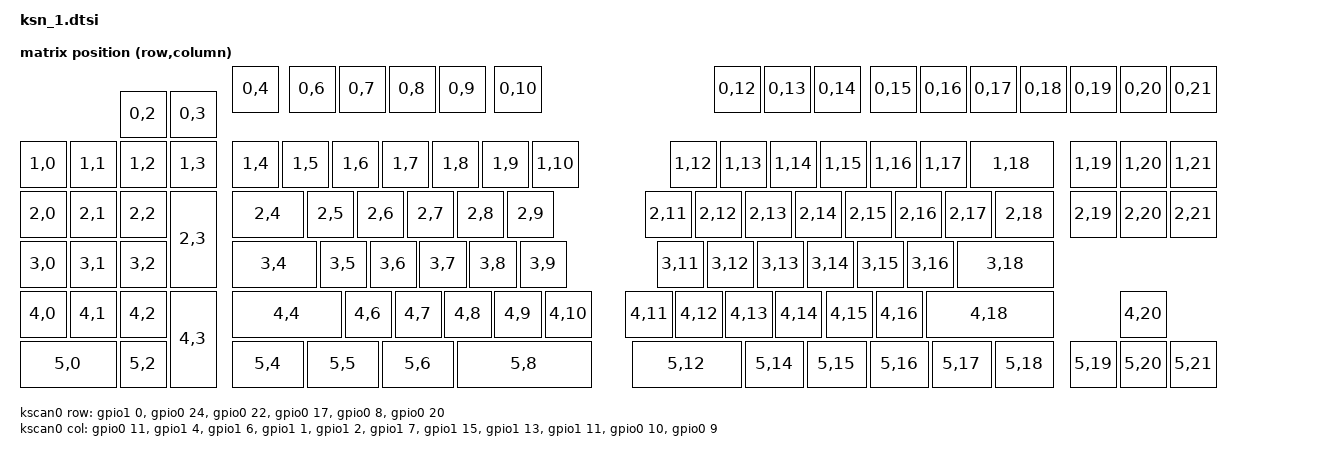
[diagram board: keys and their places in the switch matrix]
#include <dt-bindings/zmk/matrix_transform.h>
#include <physical_layouts.dtsi>

/ {
    chosen {
        zmk,kscan            = &kscan0;
        /* ZMK Studio용: matrix_transform 대신 physical layout을 chosen으로 지정 */
        zmk,physical-layout  = &default_layout;
        zmk,backlight        = &backlight;   /* 추가 */
        /* zmk,battery 는 nice!nano v2 보드 기본값(zmk,battery-nrf-vddh, 내장 VDDH 센싱)을
           그대로 사용. 예전 외부 분배저항(R-1/R-2) 기반 커스텀 vbatt 노드는 부정확한
           수치(528mV/0% 같은)를 냈기 때문에 제거함. */
    };

    default_transform: matrix_transform {
        compatible = "zmk,matrix-transform";
        columns = <22>;
        rows    = <6>;
        map = <
RC(0,2) RC(0,3) RC(0,4) RC(0,6) RC(0,7) RC(0,8) RC(0,9) RC(0,10) RC(0,12) RC(0,13) RC(0,14) RC(0,15) RC(0,16) RC(0,17) RC(0,18) RC(0,19) RC(0,20) RC(0,21)
RC(1,0) RC(1,1) RC(1,2) RC(1,3) RC(1,4) RC(1,5) RC(1,6) RC(1,7) RC(1,8) RC(1,9) RC(1,10) RC(1,12) RC(1,13) RC(1,14) RC(1,15) RC(1,16) RC(1,17) RC(1,18) RC(1,19) RC(1,20) RC(1,21)
RC(2,0) RC(2,1) RC(2,2) RC(2,3) RC(2,4) RC(2,5) RC(2,6) RC(2,7) RC(2,8) RC(2,9) RC(2,11) RC(2,12) RC(2,13) RC(2,14) RC(2,15) RC(2,16) RC(2,17) RC(2,18) RC(2,19) RC(2,20) RC(2,21)
RC(3,0) RC(3,1) RC(3,2) RC(3,4) RC(3,5) RC(3,6) RC(3,7) RC(3,8) RC(3,9) RC(3,11) RC(3,12) RC(3,13) RC(3,14) RC(3,15) RC(3,16) RC(3,18)
RC(4,0) RC(4,1) RC(4,2) RC(4,3) RC(4,4) RC(4,6) RC(4,7) RC(4,8) RC(4,9) RC(4,10) RC(4,11) RC(4,12) RC(4,13) RC(4,14) RC(4,15) RC(4,16) RC(4,18) RC(4,20)
RC(5,0) RC(5,2) RC(5,4) RC(5,5) RC(5,6) RC(5,8) RC(5,12) RC(5,14) RC(5,15) RC(5,16) RC(5,17) RC(5,18) RC(5,19) RC(5,20) RC(5,21)
        >;
    };

    /* ZMK Studio용 키 위치 정보. 실제 키보드 정면 사진 기준
       근사 배치 (단위: 1u=100). 키 순서는 default_transform의 map과 동일.
       스위치가 없는 매트릭스 자리는 map/keymap에서 모두 제외함. */
    default_layout: default_layout {
        compatible = "zmk,physical-layout";
        display-name = "KSN-1";
        transform = <&default_transform>;
        kscan = <&kscan0>;
        keys
            = <&key_physical_attrs 100 100  200  50 0 0 0>, <&key_physical_attrs 100 100  300  50 0 0 0>, <&key_physical_attrs 100 100  425   0 0 0 0>, <&key_physical_attrs 100 100  538   0 0 0 0>, <&key_physical_attrs 100 100  638   0 0 0 0>, <&key_physical_attrs 100 100  738   0 0 0 0>, <&key_physical_attrs 100 100  838   0 0 0 0>, <&key_physical_attrs 100 100  950   0 0 0 0>, <&key_physical_attrs 100 100 1388   0 0 0 0>, <&key_physical_attrs 100 100 1488   0 0 0 0>, <&key_physical_attrs 100 100 1588   0 0 0 0>, <&key_physical_attrs 100 100 1700   0 0 0 0>, <&key_physical_attrs 100 100 1800   0 0 0 0>, <&key_physical_attrs 100 100 1900   0 0 0 0>, <&key_physical_attrs 100 100 2000   0 0 0 0>, <&key_physical_attrs 100 100 2100   0 0 0 0>, <&key_physical_attrs 100 100 2200   0 0 0 0>, <&key_physical_attrs 100 100 2300   0 0 0 0>
            , <&key_physical_attrs 100 100    0 150 0 0 0>, <&key_physical_attrs 100 100  100 150 0 0 0>, <&key_physical_attrs 100 100  200 150 0 0 0>, <&key_physical_attrs 100 100  300 150 0 0 0>, <&key_physical_attrs 100 100  425 150 0 0 0>, <&key_physical_attrs 100 100  525 150 0 0 0>, <&key_physical_attrs 100 100  625 150 0 0 0>, <&key_physical_attrs 100 100  725 150 0 0 0>, <&key_physical_attrs 100 100  825 150 0 0 0>, <&key_physical_attrs 100 100  925 150 0 0 0>, <&key_physical_attrs 100 100 1025 150 0 0 0>, <&key_physical_attrs 100 100 1300 150 0 0 0>, <&key_physical_attrs 100 100 1400 150 0 0 0>, <&key_physical_attrs 100 100 1500 150 0 0 0>, <&key_physical_attrs 100 100 1600 150 0 0 0>, <&key_physical_attrs 100 100 1700 150 0 0 0>, <&key_physical_attrs 100 100 1800 150 0 0 0>, <&key_physical_attrs 175 100 1900 150 0 0 0>, <&key_physical_attrs 100 100 2100 150 0 0 0>, <&key_physical_attrs 100 100 2200 150 0 0 0>, <&key_physical_attrs 100 100 2300 150 0 0 0>
            , <&key_physical_attrs 100 100    0 250 0 0 0>, <&key_physical_attrs 100 100  100 250 0 0 0>, <&key_physical_attrs 100 100  200 250 0 0 0>, <&key_physical_attrs 100 200  300 250 0 0 0>, <&key_physical_attrs 150 100  425 250 0 0 0>, <&key_physical_attrs 100 100  575 250 0 0 0>, <&key_physical_attrs 100 100  675 250 0 0 0>, <&key_physical_attrs 100 100  775 250 0 0 0>, <&key_physical_attrs 100 100  875 250 0 0 0>, <&key_physical_attrs 100 100  975 250 0 0 0>, <&key_physical_attrs 100 100 1250 250 0 0 0>, <&key_physical_attrs 100 100 1350 250 0 0 0>, <&key_physical_attrs 100 100 1450 250 0 0 0>, <&key_physical_attrs 100 100 1550 250 0 0 0>, <&key_physical_attrs 100 100 1650 250 0 0 0>, <&key_physical_attrs 100 100 1750 250 0 0 0>, <&key_physical_attrs 100 100 1850 250 0 0 0>, <&key_physical_attrs 125 100 1950 250 0 0 0>, <&key_physical_attrs 100 100 2100 250 0 0 0>, <&key_physical_attrs 100 100 2200 250 0 0 0>, <&key_physical_attrs 100 100 2300 250 0 0 0>
            , <&key_physical_attrs 100 100    0 350 0 0 0>, <&key_physical_attrs 100 100  100 350 0 0 0>, <&key_physical_attrs 100 100  200 350 0 0 0>, <&key_physical_attrs 175 100  425 350 0 0 0>, <&key_physical_attrs 100 100  600 350 0 0 0>, <&key_physical_attrs 100 100  700 350 0 0 0>, <&key_physical_attrs 100 100  800 350 0 0 0>, <&key_physical_attrs 100 100  900 350 0 0 0>, <&key_physical_attrs 100 100 1000 350 0 0 0>, <&key_physical_attrs 100 100 1275 350 0 0 0>, <&key_physical_attrs 100 100 1375 350 0 0 0>, <&key_physical_attrs 100 100 1475 350 0 0 0>, <&key_physical_attrs 100 100 1575 350 0 0 0>, <&key_physical_attrs 100 100 1675 350 0 0 0>, <&key_physical_attrs 100 100 1775 350 0 0 0>, <&key_physical_attrs 200 100 1875 350 0 0 0>
            , <&key_physical_attrs 100 100    0 450 0 0 0>, <&key_physical_attrs 100 100  100 450 0 0 0>, <&key_physical_attrs 100 100  200 450 0 0 0>, <&key_physical_attrs 100 200  300 450 0 0 0>, <&key_physical_attrs 225 100  425 450 0 0 0>, <&key_physical_attrs 100 100  650 450 0 0 0>, <&key_physical_attrs 100 100  750 450 0 0 0>, <&key_physical_attrs 100 100  850 450 0 0 0>, <&key_physical_attrs 100 100  950 450 0 0 0>, <&key_physical_attrs 100 100 1050 450 0 0 0>, <&key_physical_attrs 100 100 1212 450 0 0 0>, <&key_physical_attrs 100 100 1312 450 0 0 0>, <&key_physical_attrs 100 100 1412 450 0 0 0>, <&key_physical_attrs 100 100 1512 450 0 0 0>, <&key_physical_attrs 100 100 1612 450 0 0 0>, <&key_physical_attrs 100 100 1712 450 0 0 0>, <&key_physical_attrs 262 100 1812 450 0 0 0>, <&key_physical_attrs 100 100 2200 450 0 0 0>
            , <&key_physical_attrs 200 100    0 550 0 0 0>, <&key_physical_attrs 100 100  200 550 0 0 0>, <&key_physical_attrs 150 100  425 550 0 0 0>, <&key_physical_attrs 150 100  575 550 0 0 0>, <&key_physical_attrs 150 100  725 550 0 0 0>, <&key_physical_attrs 275 100  875 550 0 0 0>, <&key_physical_attrs 225 100 1225 550 0 0 0>, <&key_physical_attrs 125 100 1450 550 0 0 0>, <&key_physical_attrs 125 100 1575 550 0 0 0>, <&key_physical_attrs 125 100 1700 550 0 0 0>, <&key_physical_attrs 125 100 1825 550 0 0 0>, <&key_physical_attrs 125 100 1950 550 0 0 0>, <&key_physical_attrs 100 100 2100 550 0 0 0>, <&key_physical_attrs 100 100 2200 550 0 0 0>, <&key_physical_attrs 100 100 2300 550 0 0 0>
            ;
    };

    kscan0: kscan {
        compatible      = "zmk,kscan-gpio-matrix";
        wakeup-source;
        diode-direction = "col2row";

        row-gpios
			= <&gpio1 0  (GPIO_ACTIVE_HIGH | GPIO_PULL_DOWN)>
			, <&gpio0 24 (GPIO_ACTIVE_HIGH | GPIO_PULL_DOWN)>
			, <&gpio0 22 (GPIO_ACTIVE_HIGH | GPIO_PULL_DOWN)>
			, <&gpio0 17 (GPIO_ACTIVE_HIGH | GPIO_PULL_DOWN)>
			, <&gpio0 8  (GPIO_ACTIVE_HIGH | GPIO_PULL_DOWN)>
			, <&gpio0 20 (GPIO_ACTIVE_HIGH | GPIO_PULL_DOWN)>
            ;

        col-gpios
			= <&gpio0 11 GPIO_ACTIVE_HIGH>
			, <&gpio1 4  GPIO_ACTIVE_HIGH>
			, <&gpio1 6  GPIO_ACTIVE_HIGH>
			, <&gpio1 1  GPIO_ACTIVE_HIGH>
			, <&gpio1 2  GPIO_ACTIVE_HIGH>
			, <&gpio1 7  GPIO_ACTIVE_HIGH>
			, <&gpio1 15 GPIO_ACTIVE_HIGH>
			, <&gpio1 13 GPIO_ACTIVE_HIGH>
			, <&gpio1 11 GPIO_ACTIVE_HIGH>
			, <&gpio0 10 GPIO_ACTIVE_HIGH>
			, <&gpio0 9  GPIO_ACTIVE_HIGH>
            ;
    };

};
